# SAM9X75D1G device description
Architecture: ARM926EJ-S; Family: SAM9; Series: SAM9X7
Registers are 32-bit, read-write, reset 0x0 unless marked. A register's access mark holds for its fields unless they carry their own. Offsets are from the block's base; [hi:lo] are bit positions; lines under a group give offsets from that group; {n}, {i} and the like mark numbered series; 'fields as' and 'values as' point back to an identical list.

## MCAN_XIDFE — Extended Message ID Filter Element
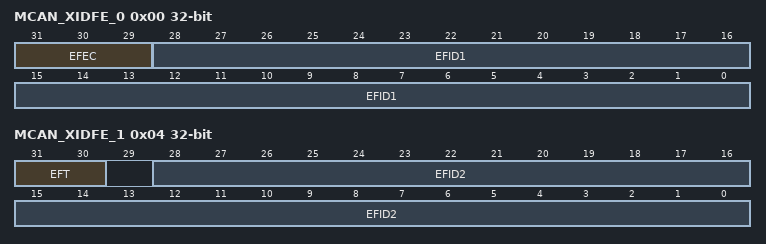
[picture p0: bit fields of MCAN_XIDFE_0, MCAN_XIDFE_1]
0x00 MCAN_XIDFE_0 reset not defined — Extended Message ID Filter Element 0
  [31:29] EFEC — Extended Filter Element Configuration
    0=DISABLE (Disable filter element); 1=STF0M (Store in Rx FIFO 0 if filter matches); 2=STF1M (Store in Rx FIFO 1 if filter matches); 3=REJECT (Reject ID if filter matches); 4=PRIORITY (Set priority if filter matches); 5=PRIF0M (Set priority and store in FIFO 0 if filter matches); 6=PRIF1M (Set priority and store in FIFO 1 if filter matches); 7=STRXBUF (Store into Rx Buffer)
  [28:0] EFID1 — Extended Filter ID 1
0x04 MCAN_XIDFE_1 reset not defined — Extended Message ID Filter Element 1
  [31:30] EFT — Extended Filter Type
    0=RANGE (Range filter from EFID1 to EFID2); 1=DUAL (Dual ID filter for EFID1 or EFID2); 2=CLASSIC (Classic filter); 3=RANGE_NO_XIDAM (Range filter from EFID1 to EFID2 with no XIDAM mask)
  [28:0] EFID2 — Extended Filter ID 2

## PIT — Periodic Interval Timer
Instances: PIT 0xFFFFFE40
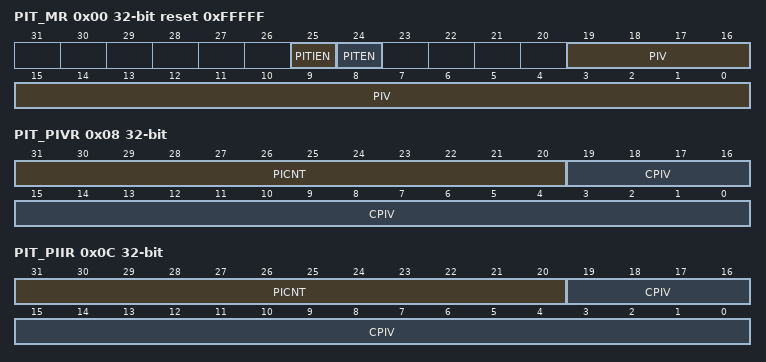
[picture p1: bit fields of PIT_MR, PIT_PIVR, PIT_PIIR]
0x00 PIT_MR reset 0xFFFFF — Mode Register
  [25] PITIEN — Periodic Interval Timer Interrupt Enable
    0=The bit PITS in PIT_SR has no effect on interrupt; 1=The bit PITS in PIT_SR asserts interrupt
  [24] PITEN — Period Interval Timer Enabled
    0=The Periodic Interval Timer is disabled when the PIV value is reached; 1=The Periodic Interval Timer is enabled
  [19:0] PIV — Periodic Interval Value
0x04 PIT_SR ro — Status Register
  [0] PITS — Periodic Interval Timer Status
    0=The Periodic Interval timer has not reached PIV since the last read of PIT_PIVR; 1=The Periodic Interval timer has reached PIV since the last read of PIT_PIVR
0x08 PIT_PIVR ro — Periodic Interval Value Register
  [31:20] PICNT — Periodic Interval Counter
  [19:0] CPIV — Current Periodic Interval Value
0x0C PIT_PIIR ro — Periodic Interval Image Register
  fields as PIT_PIVR

## PMECC — Programmable Multibit Error Correction Code Controller
Instances: PMECC 0xFFFFE000
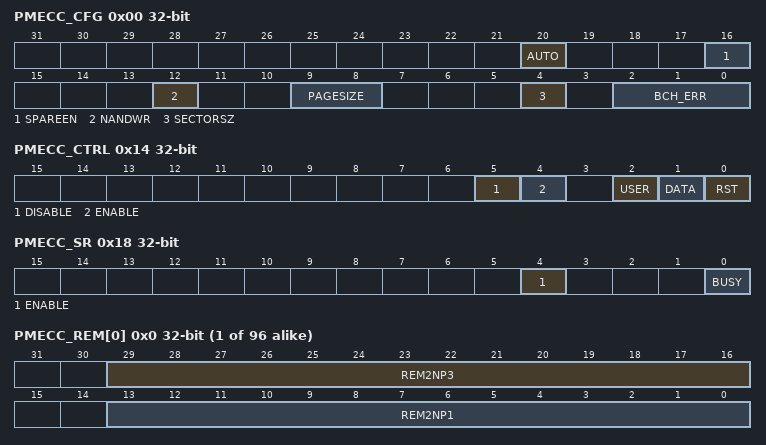
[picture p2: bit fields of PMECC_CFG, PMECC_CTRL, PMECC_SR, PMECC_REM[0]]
0x00 PMECC_CFG — PMECC Configuration Register
  [20] AUTO — Automatic Mode Enable
    0=Indicates that the spare area is not protected. In that case the ECC computation takes into account the ECC area located in the spare area. (within the start address and the end address).; 1=Indicates that the spare is error protected. In this case, the ECC computation takes into account the whole spare area minus the ECC area in the ECC computation operation.
  [16] SPAREEN — Spare Enable
    0=The spare area is skipped; 0=The spare area is skipped; 1=The spare area is protected with the last sector of data; 1=The spare area contains protected data or only redundancy information
  [12] NANDWR — NAND Write Access
    1=NAND write access
  [9:8] PAGESIZE — Number of Sectors in the Page
    0=PAGESIZE_1SEC (1 sector for main area (512 or 1024 bytes)); 1=PAGESIZE_2SEC (2 sectors for main area (1024 or 2048 bytes)); 2=PAGESIZE_4SEC (4 sectors for main area (2048 or 4096 bytes)); 3=PAGESIZE_8SEC (8 errors for main area (4096 or 8192 bytes))
  [4] SECTORSZ — Sector Size
    0=The ECC computation is based on a sector of 512 bytes; 1=The ECC computation is based on a sector of 1024 bytes
  [2:0] BCH_ERR — Error Correct Capability
    0=2 errors; 1=4 errors; 2=8 errors; 3=12 errors; 4=24 errors
0x04 PMECC_SAREA — PMECC Spare Area Size Register
  [8:0] SPARESIZE — Spare Area Size
0x08 PMECC_SADDR — PMECC Start Address Register
  [8:0] STARTADDR — ECC Area Start Address (byte oriented address)
0x0C PMECC_EADDR — PMECC End Address Register
  [8:0] ENDADDR — ECC Area End Address (byte oriented address)
0x10 PMECC_CLK — PMECC Clock Control Register
  [2:0] CLKCTRL — Clock Control Register
0x14 PMECC_CTRL wo reset not defined — PMECC Control Register
  [5] DISABLE — PMECC Module Disable
  [4] ENABLE — PMECC Module Enable
  [2] USER — Start a User Mode Phase
  [1] DATA — Start a Data Phase
  [0] RST — Reset the PMECC Module
0x18 PMECC_SR ro — PMECC Status Register
  [4] ENABLE — PMECC Module Status
    0=The PMECC module is disabled and can be configured; 1=The PMECC module is enabled and the configuration registers cannot be written
  [0] BUSY — The Kernel of the PMECC is Busy
0x1C PMECC_IER wo reset not defined (atomic set of PMECC_IMR) — PMECC Interrupt Enable register
  [0] ERRIE — Error Interrupt Enable
0x20 PMECC_IDR wo reset not defined (atomic clear of PMECC_IMR) — PMECC Interrupt Disable Register
  [0] ERRID — Error Interrupt Disable
0x24 PMECC_IMR ro — PMECC Interrupt Mask Register
  [0] ERRIM — Error Interrupt Mask
0x28 PMECC_ISR ro — PMECC Interrupt Status Register
  [7:0] ERRIS — Error Interrupt Status
{0x40+0x40*i} PMECC_ECC[{i}] (i=0..7) group
  {0x0+4j} PMECC_ECC[{j}] (j=0..10) ro — PMECC ECC x Register
    [31:0] ECC — BCH Redundancy
{0x240+0x40*i} PMECC_REM[{i}] (i=0..7) group
  {0x0+4j} PMECC_REM[{j}] (j=0..11) ro — PMECC REM x Register
    [29:16] REM2NP3 — BCH Remainder 2 * N + 3
    [13:0] REM2NP1 — BCH Remainder 2 * N + 1
